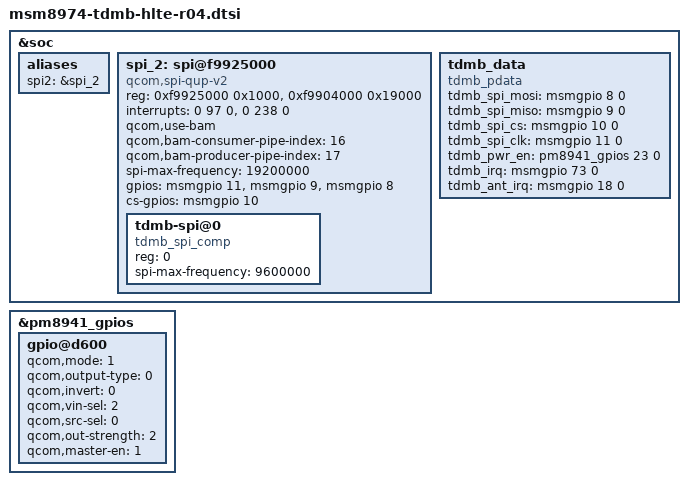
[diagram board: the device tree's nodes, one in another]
/* Copyright (c) 2012-2013, The Linux Foundation. All rights reserved.
 *
 * This program is free software; you can redistribute it and/or modify
 * it under the terms of the GNU General Public License version 2 and
 * only version 2 as published by the Free Software Foundation.
 *
 * This program is distributed in the hope that it will be useful,
 * but WITHOUT ANY WARRANTY; without even the implied warranty of
 * MERCHANTABILITY or FITNESS FOR A PARTICULAR PURPOSE.  See the
 * GNU General Public License for more details.
 */

&soc {
	aliases {
		spi2 = &spi_2;
	};

	spi_2: spi@f9925000 {
		compatible = "qcom,spi-qup-v2";
		reg = <0xf9925000 0x1000>, <0xf9904000 0x19000>;
		reg-names = "spi_physical", "spi_bam_physical";
		interrupts = <0 97 0>, <0 238 0>;
		interrupt-names = "spi_irq", "spi_bam_irq";
		qcom,use-bam;
		qcom,bam-consumer-pipe-index = <16>;
		qcom,bam-producer-pipe-index = <17>;
		spi-max-frequency = <19200000>;
		#address-cells = <1>;
		#size-cells = <0>;
		gpios = <&msmgpio 11 0>, /* CLK  */
			<&msmgpio 9 0>, /* MISO */
			<&msmgpio 8 0>; /* MOSI */
		cs-gpios = <&msmgpio 10 0>;

		tdmb-spi@0 {
			compatible = "tdmb_spi_comp";
			reg = <0>;
			spi-max-frequency = <9600000>;
		};
	};

	tdmb_data {
		compatible = "tdmb_pdata";
		tdmb_spi_mosi = <&msmgpio 8 0>;
		tdmb_spi_miso = <&msmgpio 9 0>;
		tdmb_spi_cs = <&msmgpio 10 0>;
		tdmb_spi_clk = <&msmgpio 11 0>;
		tdmb_pwr_en = <&pm8941_gpios 23 0>;
		tdmb_irq = <&msmgpio 73 0>;
		tdmb_ant_irq = <&msmgpio 18 0>;
	};
};

&pm8941_gpios {
	gpio@d600 { /* GPIO 23 */
		/* TDMB_EN */
		qcom,mode = <1>;		/* Digital output */
		qcom,output-type = <0>;		/* CMOS logic */
		qcom,invert = <0>;		/* Output low initially */
		qcom,vin-sel = <2>;		/* PM8941 S3 = 1.8 V */
		qcom,src-sel = <0>;		/* Constant */
		qcom,out-strength = <2>;	/* Medium drive strength */
		qcom,master-en = <1>;		/* Enable GPIO */
	};
};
